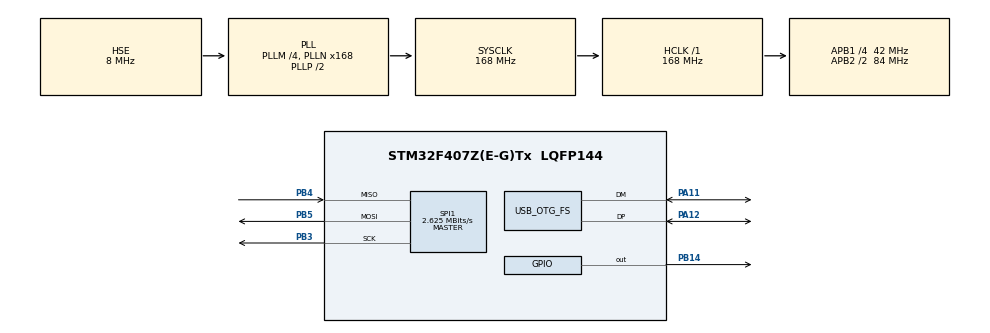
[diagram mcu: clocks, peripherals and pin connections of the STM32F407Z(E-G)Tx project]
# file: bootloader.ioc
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FREERTOS.MEMORY_ALLOCATION=0
FREERTOS.Tasks01=defaultTask,0,128,StartDefaultTask,Default,NULL,Dynamic,NULL,NULL
FREERTOS.configTOTAL_HEAP_SIZE=20480
Mcu.Family=STM32F4
Mcu.Name=STM32F407Z(E-G)Tx
Mcu.Package=LQFP144
NVIC.OTG_FS_IRQn=true\:5\:0\:false\:false\:true\:true\:false\:true\:true
NVIC.PriorityGroup=NVIC_PRIORITYGROUP_4
NVIC.TIM6_DAC_IRQn=true\:6\:0\:true\:false\:true\:true\:true\:true\:true
NVIC.TIM7_IRQn=true\:6\:0\:true\:false\:true\:true\:true\:true\:true
PA11.Mode=Device_Only
PA11.Signal=USB_OTG_FS_DM
PA12.Mode=Device_Only
PA12.Signal=USB_OTG_FS_DP
PA13.Mode=Serial_Wire
PA13.Signal=SYS_JTMS-SWDIO
PA14.Mode=Serial_Wire
PA14.Signal=SYS_JTCK-SWCLK
PB14.GPIO_PuPd=GPIO_PULLUP
PB14.Signal=GPIO_Output
PB3.Mode=Full_Duplex_Master
PB3.Signal=SPI1_SCK
PB4.Mode=Full_Duplex_Master
PB4.Signal=SPI1_MISO
PB5.Mode=Full_Duplex_Master
PB5.Signal=SPI1_MOSI
PH0-OSC_IN.Mode=HSE-External-Oscillator
PH0-OSC_IN.Signal=RCC_OSC_IN
PH1-OSC_OUT.Mode=HSE-External-Oscillator
PH1-OSC_OUT.Signal=RCC_OSC_OUT
ProjectManager.HeapSize=0x200
ProjectManager.StackSize=0x400
ProjectManager.TargetToolchain=STM32CubeIDE
RCC.48MHZClocksFreq_Value=48000000
RCC.AHBFreq_Value=168000000
RCC.APB1CLKDivider=RCC_HCLK_DIV4
RCC.APB1Freq_Value=42000000
RCC.APB1TimFreq_Value=84000000
RCC.APB2CLKDivider=RCC_HCLK_DIV2
RCC.APB2Freq_Value=84000000
RCC.APB2TimFreq_Value=168000000
RCC.CortexFreq_Value=168000000
RCC.HCLKFreq_Value=168000000
RCC.HSE_VALUE=8000000
RCC.HSI_VALUE=16000000
RCC.LSE_VALUE=32768
RCC.PLLM=4
RCC.PLLN=168
RCC.PLLQ=7
RCC.SYSCLKFreq_VALUE=168000000
RCC.SYSCLKSource=RCC_SYSCLKSOURCE_PLLCLK
RCC.VCOOutputFreq_Value=336000000
SPI1.BaudRatePrescaler=SPI_BAUDRATEPRESCALER_32
SPI1.CalculateBaudRate=2.625 MBits/s
SPI1.Direction=SPI_DIRECTION_2LINES
SPI1.Mode=SPI_MODE_MASTER
SPI1.VirtualType=VM_MASTER
TIM6.Period=1000
TIM6.Prescaler=84
TIM7.Period=1000
TIM7.Prescaler=83
USB_DEVICE.CLASS_NAME_FS=CDC
USB_DEVICE.VirtualMode-CDC_FS=Cdc
USB_DEVICE.VirtualModeFS=Cdc_FS
USB_OTG_FS.VirtualMode=Device_Only
VP_FREERTOS_VS_CMSIS_V1.Mode=CMSIS_V1
VP_TIM6_VS_ClockSourceINT.Mode=Enable_Timer
VP_TIM7_VS_ClockSourceINT.Mode=Enable_Timer
VP_USB_DEVICE_VS_USB_DEVICE_CDC_FS.Mode=CDC_FS
board=custom

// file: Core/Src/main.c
/* USER CODE BEGIN Header */
/**
  ******************************************************************************
  * @file           : main.c
  * @brief          : Main program body
  ******************************************************************************
  * @attention
  *
  * Copyright (c) 2024 STMicroelectronics.
  * All rights reserved.
  *
  * This software is licensed under terms that can be found in the LICENSE file
  * in the root directory of this software component.
  * If no LICENSE file comes with this software, it is provided AS-IS.
  *
  ******************************************************************************
  */
/* USER CODE END Header */
#include "main.h"
#include "cmsis_os.h"
#include "usb_device.h"

/* USER CODE BEGIN Includes */
#include "mainApp.h"
/* USER CODE END Includes */

SPI_HandleTypeDef hspi1;

TIM_HandleTypeDef htim6;
TIM_HandleTypeDef htim7;

osThreadId defaultTaskHandle;

void SystemClock_Config(void);
static void MX_GPIO_Init(void);
static void MX_TIM6_Init(void);
static void MX_SPI1_Init(void);
static void MX_TIM7_Init(void);
void StartDefaultTask(void const * argument);

int main(void)
{

  /* MCU Configuration--------------------------------------------------------*/

  /* Reset of all peripherals, Initializes the Flash interface and the Systick. */
  HAL_Init();

  /* Configure the system clock */
  SystemClock_Config();

  /* Initialize all configured peripherals */
  MX_GPIO_Init();
  MX_TIM6_Init();
  MX_SPI1_Init();
  MX_TIM7_Init();
  /* USER CODE BEGIN 2 */
  HAL_GPIO_WritePin(GPIOB, GPIO_PIN_14, GPIO_PIN_SET);
  /* USER CODE END 2 */

  /* Create the thread(s) */
  /* definition and creation of defaultTask */
  osThreadDef(defaultTask, StartDefaultTask, osPriorityNormal, 0, 128);
  defaultTaskHandle = osThreadCreate(osThread(defaultTask), NULL);

  /* Start scheduler */
  osKernelStart();

  /* We should never get here as control is now taken by the scheduler */

  /* Infinite loop */
  while (1)
  {

  }
}

void SystemClock_Config(void)
{
  RCC_OscInitTypeDef RCC_OscInitStruct = {0};
  RCC_ClkInitTypeDef RCC_ClkInitStruct = {0};

  /** Configure the main internal regulator output voltage
  */
  __HAL_RCC_PWR_CLK_ENABLE();
  __HAL_PWR_VOLTAGESCALING_CONFIG(PWR_REGULATOR_VOLTAGE_SCALE1);

  /** Initializes the RCC Oscillators according to the specified parameters
  * in the RCC_OscInitTypeDef structure.
  */
  RCC_OscInitStruct.OscillatorType = RCC_OSCILLATORTYPE_HSE;
  RCC_OscInitStruct.HSEState = RCC_HSE_ON;
  RCC_OscInitStruct.PLL.PLLState = RCC_PLL_ON;
  RCC_OscInitStruct.PLL.PLLSource = RCC_PLLSOURCE_HSE;
  RCC_OscInitStruct.PLL.PLLM = 4;
  RCC_OscInitStruct.PLL.PLLN = 168;
  RCC_OscInitStruct.PLL.PLLP = RCC_PLLP_DIV2;
  RCC_OscInitStruct.PLL.PLLQ = 7;
  if (HAL_RCC_OscConfig(&RCC_OscInitStruct) != HAL_OK)
  {
    Error_Handler();
  }

  /** Initializes the CPU, AHB and APB buses clocks
  */
  RCC_ClkInitStruct.ClockType = RCC_CLOCKTYPE_HCLK|RCC_CLOCKTYPE_SYSCLK
                              |RCC_CLOCKTYPE_PCLK1|RCC_CLOCKTYPE_PCLK2;
  RCC_ClkInitStruct.SYSCLKSource = RCC_SYSCLKSOURCE_PLLCLK;
  RCC_ClkInitStruct.AHBCLKDivider = RCC_SYSCLK_DIV1;
  RCC_ClkInitStruct.APB1CLKDivider = RCC_HCLK_DIV4;
  RCC_ClkInitStruct.APB2CLKDivider = RCC_HCLK_DIV2;

  if (HAL_RCC_ClockConfig(&RCC_ClkInitStruct, FLASH_LATENCY_5) != HAL_OK)
  {
    Error_Handler();
  }
}

static void MX_SPI1_Init(void)
{

  /* SPI1 parameter configuration*/
  hspi1.Instance = SPI1;
  hspi1.Init.Mode = SPI_MODE_MASTER;
  hspi1.Init.Direction = SPI_DIRECTION_2LINES;
  hspi1.Init.DataSize = SPI_DATASIZE_8BIT;
  hspi1.Init.CLKPolarity = SPI_POLARITY_LOW;
  hspi1.Init.CLKPhase = SPI_PHASE_1EDGE;
  hspi1.Init.NSS = SPI_NSS_SOFT;
  hspi1.Init.BaudRatePrescaler = SPI_BAUDRATEPRESCALER_32;
  hspi1.Init.FirstBit = SPI_FIRSTBIT_MSB;
  hspi1.Init.TIMode = SPI_TIMODE_DISABLE;
  hspi1.Init.CRCCalculation = SPI_CRCCALCULATION_DISABLE;
  hspi1.Init.CRCPolynomial = 10;
  if (HAL_SPI_Init(&hspi1) != HAL_OK)
  {
    Error_Handler();
  }

}

static void MX_TIM6_Init(void)
{

  TIM_MasterConfigTypeDef sMasterConfig = {0};

  htim6.Instance = TIM6;
  htim6.Init.Prescaler = 84;
  htim6.Init.CounterMode = TIM_COUNTERMODE_UP;
  htim6.Init.Period = 1000;
  htim6.Init.AutoReloadPreload = TIM_AUTORELOAD_PRELOAD_DISABLE;
  if (HAL_TIM_Base_Init(&htim6) != HAL_OK)
  {
    Error_Handler();
  }
  sMasterConfig.MasterOutputTrigger = TIM_TRGO_RESET;
  sMasterConfig.MasterSlaveMode = TIM_MASTERSLAVEMODE_DISABLE;
  if (HAL_TIMEx_MasterConfigSynchronization(&htim6, &sMasterConfig) != HAL_OK)
  {
    Error_Handler();
  }

}

static void MX_TIM7_Init(void)
{

  TIM_MasterConfigTypeDef sMasterConfig = {0};

  htim7.Instance = TIM7;
  htim7.Init.Prescaler = 83;
  htim7.Init.CounterMode = TIM_COUNTERMODE_UP;
  htim7.Init.Period = 1000;
  htim7.Init.AutoReloadPreload = TIM_AUTORELOAD_PRELOAD_DISABLE;
  if (HAL_TIM_Base_Init(&htim7) != HAL_OK)
  {
    Error_Handler();
  }
  sMasterConfig.MasterOutputTrigger = TIM_TRGO_RESET;
  sMasterConfig.MasterSlaveMode = TIM_MASTERSLAVEMODE_DISABLE;
  if (HAL_TIMEx_MasterConfigSynchronization(&htim7, &sMasterConfig) != HAL_OK)
  {
    Error_Handler();
  }

}

static void MX_GPIO_Init(void)
{
  GPIO_InitTypeDef GPIO_InitStruct = {0};

  /* GPIO Ports Clock Enable */
  __HAL_RCC_GPIOH_CLK_ENABLE();
  __HAL_RCC_GPIOB_CLK_ENABLE();
  __HAL_RCC_GPIOA_CLK_ENABLE();

  /*Configure GPIO pin Output Level */
  HAL_GPIO_WritePin(GPIOB, GPIO_PIN_14, GPIO_PIN_RESET);

  /*Configure GPIO pin : PB14 */
  GPIO_InitStruct.Pin = GPIO_PIN_14;
  GPIO_InitStruct.Mode = GPIO_MODE_OUTPUT_PP;
  GPIO_InitStruct.Pull = GPIO_PULLUP;
  GPIO_InitStruct.Speed = GPIO_SPEED_FREQ_LOW;
  HAL_GPIO_Init(GPIOB, &GPIO_InitStruct);

}

void StartDefaultTask(void const * argument)
{
  /* init code for USB_DEVICE */
  MX_USB_DEVICE_Init();
  /* USER CODE BEGIN 5 */
  /* Infinite loop */
  for(;;)
  {
	  mainApp();
    osDelay(1);
  }
  /* USER CODE END 5 */
}

void Error_Handler(void)
{
  __disable_irq();
  while (1)
  {
  }
}
